# ATmega169PA register map
Vendor: Atmel; File version: 1.0
CPU: other r0p0, little endian, no MPU, no FPU, 4 interrupt priority bits
Registers are 8-bit, read-write, reset 0x0 unless marked. A register's access mark holds for its fields unless they carry their own. Offsets are from the block's base; [hi:lo] are bit positions; {n}, {i} and the like mark numbered series.

## LOCKBIT — Lockbits
Base 0x00000000
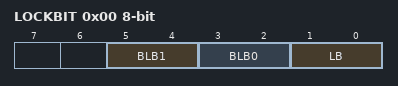
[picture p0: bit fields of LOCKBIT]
0x00 LOCKBIT
  [5:4] BLB1 — Boot Loader Protection Mode
    0=LPM_SPM_DISABLE (LPM and SPM prohibited in Boot Section); 1=LPM_DISABLE (LPM prohibited in Boot Section); 2=SPM_DISABLE (SPM prohibited in Boot Section); 3=NO_LOCK (No lock on SPM and LPM in Boot Section)
  [3:2] BLB0 — Boot Loader Protection Mode
    0=LPM_SPM_DISABLE (LPM and SPM prohibited in Application Section); 1=LPM_DISABLE (LPM prohibited in Application Section); 2=SPM_DISABLE (SPM prohibited in Application Section); 3=NO_LOCK (No lock on SPM and LPM in Application Section)
  [1:0] LB — Memory Lock
    0=PROG_VER_DISABLED (Further programming and verification disabled); 2=PROG_DISABLED (Further programming disabled); 3=NO_LOCK (No memory lock features enabled)

## PORTA — I/O Port
Base 0x00000020
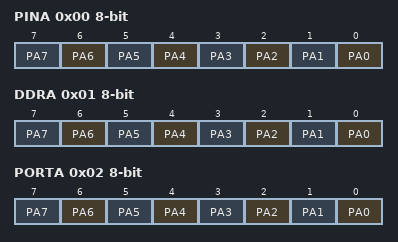
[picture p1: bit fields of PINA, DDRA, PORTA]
0x00 PINA — Port A Input Pins
  [n] PA{n} (n=0..7) — Pin A{n}
0x01 DDRA — Port A Data Direction Register
  [n] PA{n} (n=0..7) — Pin A{n}
0x02 PORTA — Port A Data Register
  [n] PA{n} (n=0..7) — Pin A{n}

## PORTB — I/O Port
Base 0x00000023
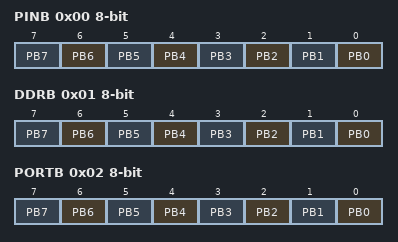
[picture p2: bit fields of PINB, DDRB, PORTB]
0x00 PINB — Port B Input Pins
  [n] PB{n} (n=0..7) — Pin B{n}
0x01 DDRB — Port B Data Direction Register
  [n] PB{n} (n=0..7) — Pin B{n}
0x02 PORTB — Port B Data Register
  [n] PB{n} (n=0..7) — Pin B{n}

## PORTC — I/O Port
Base 0x00000026
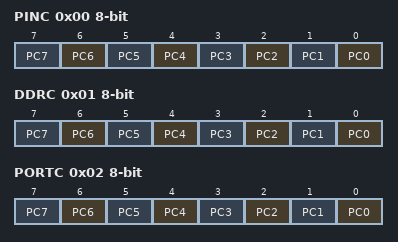
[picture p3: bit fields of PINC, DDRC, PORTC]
0x00 PINC — Port C Input Pins
  [n] PC{n} (n=0..7) — Pin C{n}
0x01 DDRC — Port C Data Direction Register
  [n] PC{n} (n=0..7) — Pin C{n}
0x02 PORTC — Port C Data Register
  [n] PC{n} (n=0..7) — Pin C{n}

## PORTD — I/O Port
Base 0x00000029
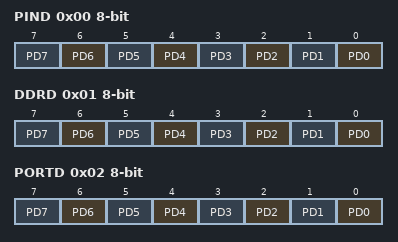
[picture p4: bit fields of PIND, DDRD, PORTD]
0x00 PIND — Port D Input Pins
  [n] PD{n} (n=0..7) — Pin D{n}
0x01 DDRD — Port D Data Direction Register
  [n] PD{n} (n=0..7) — Pin D{n}
0x02 PORTD — Port D Data Register
  [n] PD{n} (n=0..7) — Pin D{n}

## PORTE — I/O Port
Base 0x0000002C
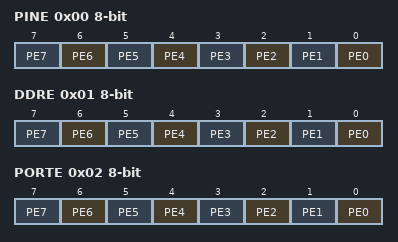
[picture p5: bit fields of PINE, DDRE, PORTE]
0x00 PINE — Input Pins, Port E
  [n] PE{n} (n=0..7) — Pin E{n}
0x01 DDRE — Data Direction Register, Port E
  [n] PE{n} (n=0..7) — Pin E{n}
0x02 PORTE — Data Register, Port E
  [n] PE{n} (n=0..7) — Pin E{n}

## PORTF — I/O Port
Base 0x0000002F
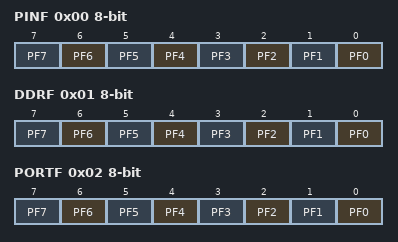
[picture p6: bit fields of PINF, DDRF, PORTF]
0x00 PINF — Input Pins, Port F
  [n] PF{n} (n=0..7) — Pin F{n}
0x01 DDRF — Data Direction Register, Port F
  [n] PF{n} (n=0..7) — Pin F{n}
0x02 PORTF — Data Register, Port F
  [n] PF{n} (n=0..7) — Pin F{n}

## PORTG — I/O Port
Base 0x00000032
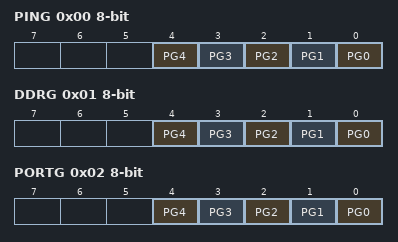
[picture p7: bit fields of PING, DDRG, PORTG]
0x00 PING — Port G Input Pins
  [n] PG{n} (n=0..4) — Pin G{n}
0x01 DDRG — Port G Data Direction Register
  [n] PG{n} (n=0..4) — Pin G{n}
0x02 PORTG — Port G Data Register
  [n] PG{n} (n=0..4) — Pin G{n}

## SPI — Serial Peripheral Interface
Base 0x0000004C
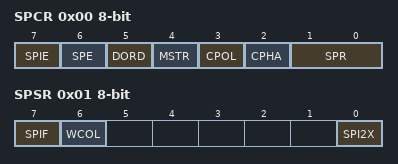
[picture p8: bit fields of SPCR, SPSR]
0x00 SPCR — SPI Control Register
  [7] SPIE — SPI Interrupt Enable
  [6] SPE — SPI Enable
  [5] DORD — Data Order
  [4] MSTR — Master/Slave Select
  [3] CPOL — Clock polarity
  [2] CPHA — Clock Phase
  [1:0] SPR — SPI Clock Rate Selects
    0=fosc/4; 1=fosc/16; 2=fosc/64; 3=fosc/128
0x01 SPSR — SPI Status Register
  [7] SPIF — SPI Interrupt Flag
  [6] WCOL — Write Collision Flag
  [0] SPI2X — Double SPI Speed Bit
0x02 SPDR — SPI Data Register
  [7:0] SPDR — SPI Data bits

## TC0 — Timer/Counter, 8-bit
Base 0x00000035
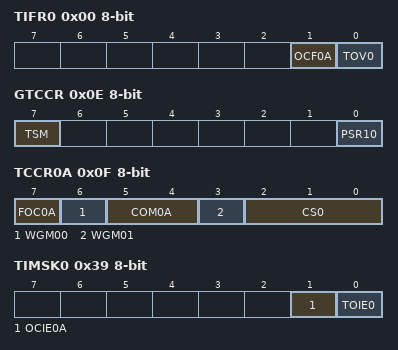
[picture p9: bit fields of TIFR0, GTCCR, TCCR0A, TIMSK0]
0x00 TIFR0 — Timer/Counter0 Interrupt Flag register
  [1] OCF0A — Timer/Counter0 Output Compare Flag 0
  [0] TOV0 — Timer/Counter0 Overflow Flag
0x0E GTCCR — General Timer/Control Register
  [7] TSM — Timer/Counter Synchronization Mode
  [0] PSR10 — Prescaler Reset Timer/Counter1 and Timer/Counter0
0x0F TCCR0A — Timer/Counter0 Control Register
  [7] FOC0A — Force Output Compare
  [6] WGM00 — Waveform Generation Mode 0
    0=Normal; 1=CTC
  [5:4] COM0A — Compare Match Output Modes
  [3] WGM01 — Waveform Generation Mode 1
  [2:0] CS0 — Clock Selects
    0=No Clock Source (Stopped); 1=Running, No Prescaling; 2=Running, CLK/8; 3=Running, CLK/64; 4=Running, CLK/256; 5=Running, CLK/1024; 6=Running, ExtClk Tx Falling Edge; 7=Running, ExtClk Tx Rising Edge
0x11 TCNT0 — Timer/Counter0
  [7:0] TCNT0 — Timer/Counter0 bits
0x12 OCR0A — Timer/Counter0 Output Compare Register
  [7:0] OCR0A — Timer/Counter0 Output Compare A
0x39 TIMSK0 — Timer/Counter0 Interrupt Mask Register
  [1] OCIE0A — Timer/Counter0 Output Compare Match Interrupt Enable
  [0] TOIE0 — Timer/Counter0 Overflow Interrupt Enable
